# STM32F3x8 register map
File version: 1.5
CPU: CM4 r1p0, little endian, no MPU, no FPU, 3 interrupt priority bits
Registers are 32-bit, read-write, reset 0x0 unless marked. A register's access mark holds for its fields unless they carry their own. Offsets are from the block's base; [hi:lo] are bit positions; {n}, {i} and the like mark numbered series; 'fields as' and 'values as' point back to an identical list.

## CRC — cyclic redundancy check calculation unit
Base 0x40023000
0x00 DR reset 0xFFFFFFFF — Data register
  [31:0] DR — Data register bits
0x04 IDR — Independent data register
  [7:0] IDR — General-purpose 8-bit data register bits
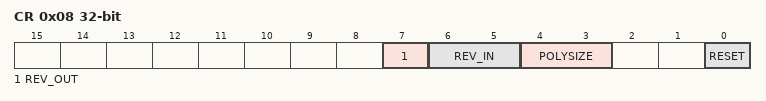
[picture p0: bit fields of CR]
0x08 CR — Control register
  [7] REV_OUT — Reverse output data
  [6:5] REV_IN — Reverse input data
  [4:3] POLYSIZE — Polynomial size
  [0] RESET — reset bit
0x10 INIT reset 0xFFFFFFFF — Initial CRC value
  [31:0] INIT — Programmable initial CRC value
0x14 POL reset 0x4C11DB7 — CRC polynomial
  [31:0] POL — Programmable polynomial

## Flash
Base 0x40022000
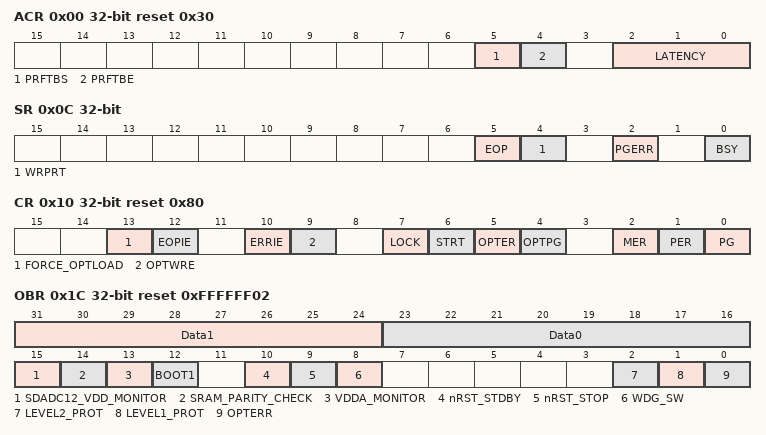
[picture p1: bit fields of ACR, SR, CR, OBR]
0x00 ACR access per field reset 0x30 — Flash access control register
  [5] PRFTBS ro, [4] PRFTBE rw, [2:0] LATENCY rw
0x04 KEYR wo — Flash key register
  [31:0] FKEYR — Flash Key
0x08 OPTKEYR wo — Flash option key register
  [31:0] OPTKEYR — Option byte key
0x0C SR access per field — Flash status register
  [5] EOP rw — End of operation
  [4] WRPRT rw — Write protection error
  [2] PGERR rw — Programming error
  [0] BSY ro — Busy
0x10 CR reset 0x80 — Flash control register
  [13] FORCE_OPTLOAD — Force option byte loading
  [12] EOPIE — End of operation interrupt enable
  [10] ERRIE — Error interrupt enable
  [9] OPTWRE — Option bytes write enable
  [7] LOCK
  [6] STRT — Start
  [5] OPTER — Option byte erase
  [4] OPTPG — Option byte programming
  [2] MER — Mass erase
  [1] PER — Page erase
  [0] PG — Programming
0x14 AR wo — Flash address register
  [31:0] FAR — Flash address
0x1C OBR ro reset 0xFFFFFF02 — Option byte register
  [31:24] Data1
  [23:16] Data0
  [15] SDADC12_VDD_MONITOR
  [14] SRAM_PARITY_CHECK
  [13] VDDA_MONITOR
  [12] BOOT1
  [10] nRST_STDBY
  [9] nRST_STOP
  [8] WDG_SW
  [2] LEVEL2_PROT — Level 2 protection status
  [1] LEVEL1_PROT — Level 1 protection status
  [0] OPTERR — Option byte error
0x20 WRPR ro reset 0xFFFFFFFF — Write protection register
  [31:0] WRP — Write protect

## DMA1 — DMA controller 1
Base 0x40020000
Same registers: DMA2 0x40020400
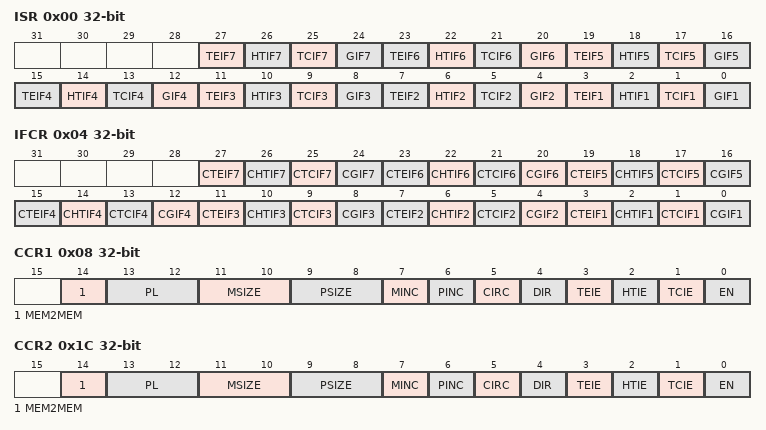
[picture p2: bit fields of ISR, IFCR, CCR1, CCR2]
0x00 ISR ro — DMA interrupt status register (DMA_ISR)
  [4n-1] TEIF{n} (n=1..7) — Channel {n} Transfer Error flag
  [4n-2] HTIF{n} (n=1..7) — Channel {n} Half Transfer Complete flag
  [4n-3] TCIF{n} (n=1..7) — Channel {n} Transfer Complete flag
  [4n-4] GIF{n} (n=1..7) — Channel {n} Global interrupt flag
0x04 IFCR wo — DMA interrupt flag clear register (DMA_IFCR)
  [4n-1] CTEIF{n} (n=1..7) — Channel {n} Transfer Error clear
  [4n-2] CHTIF{n} (n=1..7) — Channel {n} Half Transfer clear
  [4n-3] CTCIF{n} (n=1..7) — Channel {n} Transfer Complete clear
  [4n-4] CGIF{n} (n=1..7) — Channel {n} Global interrupt clear
0x08 CCR1 — DMA channel configuration register (DMA_CCR)
  [14] MEM2MEM — Memory to memory mode
  [13:12] PL — Channel Priority level
  [11:10] MSIZE — Memory size
  [9:8] PSIZE — Peripheral size
  [7] MINC — Memory increment mode
  [6] PINC — Peripheral increment mode
  [5] CIRC — Circular mode
  [4] DIR — Data transfer direction
  [3] TEIE — Transfer error interrupt enable
  [2] HTIE — Half Transfer interrupt enable
  [1] TCIE — Transfer complete interrupt enable
  [0] EN — Channel enable
0x0C CNDTR1 — DMA channel 1 number of data register
  [15:0] NDT — Number of data to transfer
0x10 CPAR1 — DMA channel 1 peripheral address register
  [31:0] PA — Peripheral address
{0x0+0x14*i} CMAR{i} (i=1..7) — DMA channel {i} memory address register
  [31:0] MA — Memory address
0x1C CCR2 — DMA channel configuration register (DMA_CCR)
  fields as CCR1
0x20 CNDTR2 — DMA channel 2 number of data register
  [15:0] NDT — Number of data to transfer
0x24 CPAR2 — DMA channel 2 peripheral address register
  [31:0] PA — Peripheral address
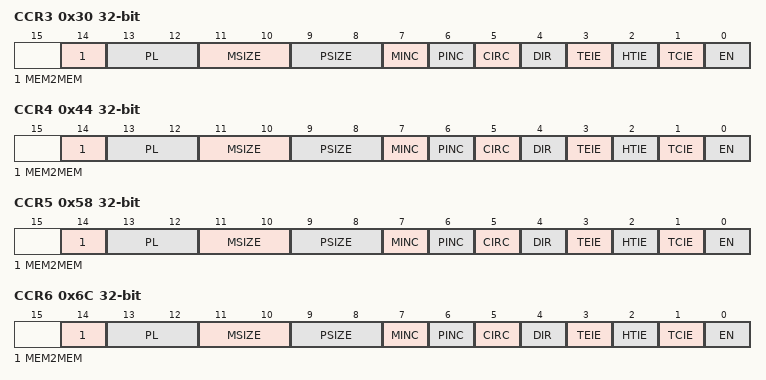
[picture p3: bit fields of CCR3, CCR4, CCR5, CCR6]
0x30 CCR3 — DMA channel configuration register (DMA_CCR)
  fields as CCR1
0x34 CNDTR3 — DMA channel 3 number of data register
  [15:0] NDT — Number of data to transfer
0x38 CPAR3 — DMA channel 3 peripheral address register
  [31:0] PA — Peripheral address
0x44 CCR4 — DMA channel configuration register (DMA_CCR)
  fields as CCR1
0x48 CNDTR4 — DMA channel 4 number of data register
  [15:0] NDT — Number of data to transfer
0x4C CPAR4 — DMA channel 4 peripheral address register
  [31:0] PA — Peripheral address
0x58 CCR5 — DMA channel configuration register (DMA_CCR)
  fields as CCR1
0x5C CNDTR5 — DMA channel 5 number of data register
  [15:0] NDT — Number of data to transfer
0x60 CPAR5 — DMA channel 5 peripheral address register
  [31:0] PA — Peripheral address
0x6C CCR6 — DMA channel configuration register (DMA_CCR)
  fields as CCR1
0x70 CNDTR6 — DMA channel 6 number of data register
  [15:0] NDT — Number of data to transfer
0x74 CPAR6 — DMA channel 6 peripheral address register
  [31:0] PA — Peripheral address
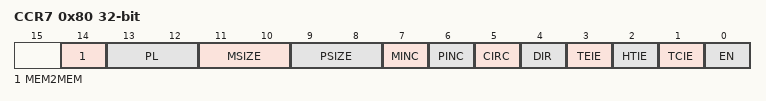
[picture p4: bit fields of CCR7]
0x80 CCR7 — DMA channel configuration register (DMA_CCR)
  fields as CCR1
0x84 CNDTR7 — DMA channel 7 number of data register
  [15:0] NDT — Number of data to transfer
0x88 CPAR7 — DMA channel 7 peripheral address register
  [31:0] PA — Peripheral address
